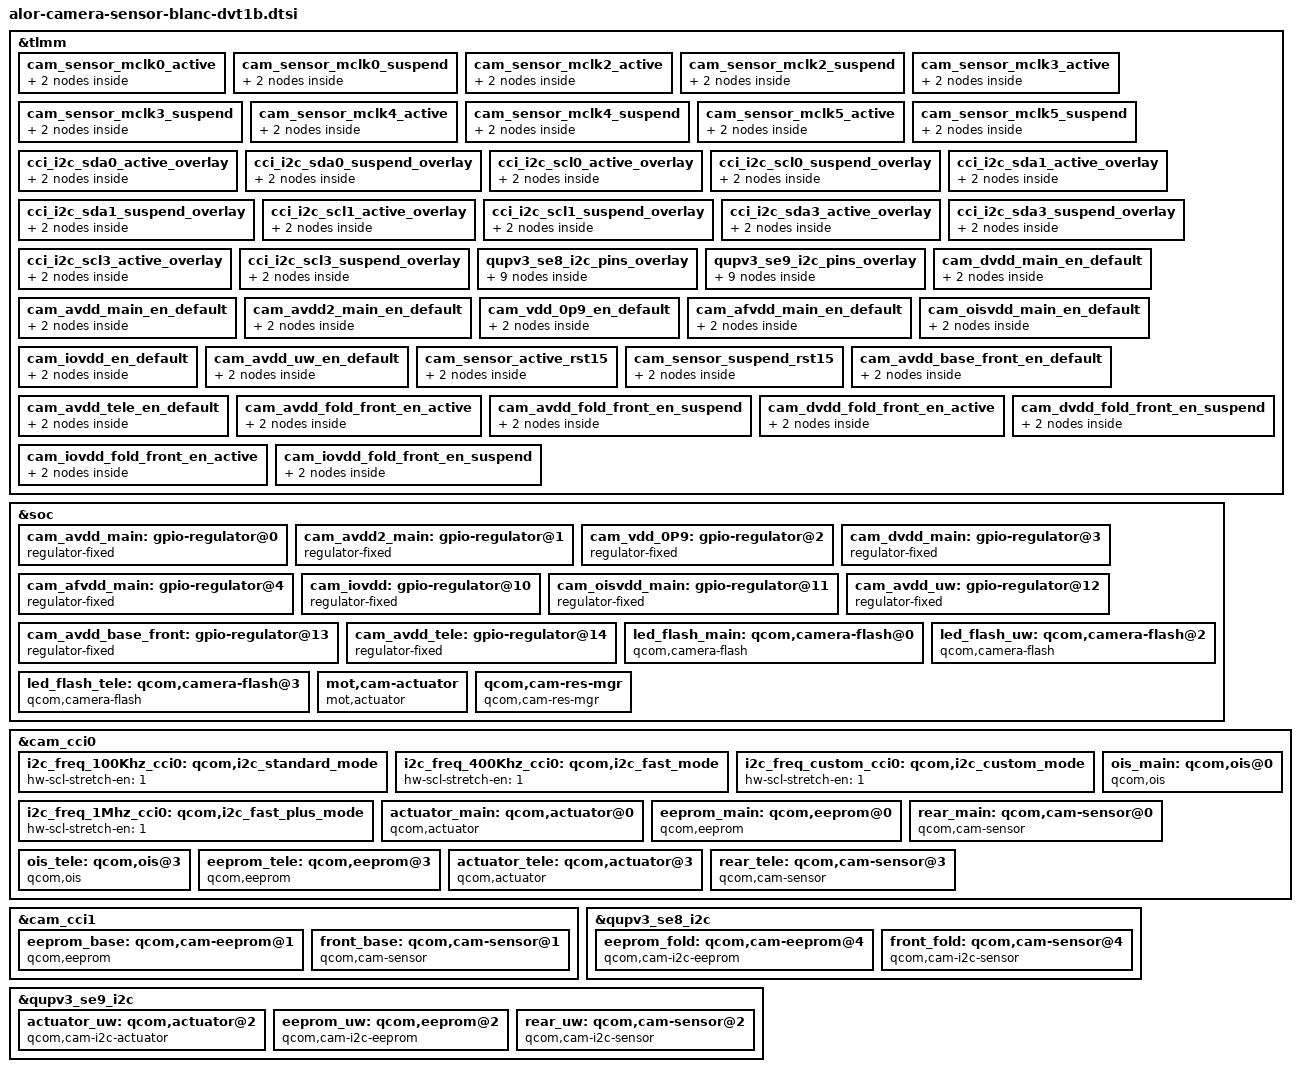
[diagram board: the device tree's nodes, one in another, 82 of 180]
// SPDX-License-Identifier: BSD-3-Clause
/*
 * Copyright (c) 2024 Qualcomm Innovation Center, Inc. All rights reserved.
 */

#include <dt-bindings/msm-camera.h>

&tlmm {
	cam_sensor_mclk0_active: cam_sensor_mclk0_active {
		/* MCLK0 */
		mux {
			pins = "gpio89";
			function = "cam_mclk";
		};

		config {
			pins = "gpio89";
			bias-disable; /* No PULL */
			drive-strength = <4>; /* 4 MA */
		};
	};

	cam_sensor_mclk0_suspend: cam_sensor_mclk0_suspend {
		/* MCLK0 */
		mux {
			pins = "gpio89";
			function = "cam_mclk";
		};

		config {
			pins = "gpio89";
			bias-pull-down; /* PULL DOWN */
			drive-strength = <4>; /* 4 MA */
		};
	};

	cam_sensor_mclk2_active: cam_sensor_mclk2_active {
		/* MCLK2 */
		mux {
			pins = "gpio91";
			function = "cam_mclk";
		};

		config {
			pins = "gpio91";
			bias-disable; /* No PULL */
			drive-strength = <4>; /* 4 MA */
		};
	};

	cam_sensor_mclk2_suspend: cam_sensor_mclk2_suspend {
		/* MCLK2 */
		mux {
			pins = "gpio91";
			function = "cam_mclk";
		};

		config {
			pins = "gpio91";
			bias-pull-down; /* PULL DOWN */
			drive-strength = <4>; /* 4 MA */
		};
	};

	cam_sensor_mclk3_active: cam_sensor_mclk3_active {
		/* MCLK3 */
		mux {
			pins = "gpio92";
			function = "cam_mclk";
		};

		config {
			pins = "gpio92";
			bias-disable; /* No PULL */
			drive-strength = <4>; /* 4 MA */
		};
	};

	cam_sensor_mclk3_suspend: cam_sensor_mclk3_suspend {
		/* MCLK3 */
		mux {
			pins = "gpio92";
			function = "cam_mclk";
		};

		config {
			pins = "gpio92";
			bias-pull-down; /* PULL DOWN */
			drive-strength = <4>; /* 4 MA */
		};
	};

	cam_sensor_mclk4_active: cam_sensor_mclk4_active {
		/* MCLK4 */
		mux {
			pins = "gpio93";
			function = "cam_asc_mclk4";
		};

		config {
			pins = "gpio93";
			bias-disable; /* No PULL */
			drive-strength = <6>; /* 6 MA */
		};
	};

	cam_sensor_mclk4_suspend: cam_sensor_mclk4_suspend {
		/* MCLK4 */
		mux {
			pins = "gpio93";
			function = "cam_asc_mclk4";
		};

		config {
			pins = "gpio93";
			bias-pull-down; /* PULL DOWN */
			drive-strength = <6>; /* 6 MA */
		};
	};

	cam_sensor_mclk5_active: cam_sensor_mclk5_active {
		/* MCLK5 */
		mux {
			pins = "gpio94";
			function = "cam_mclk";
		};

		config {
			pins = "gpio94";
			bias-disable; /* No PULL */
			drive-strength = <4>; /* 4 MA */
		};
	};

	cam_sensor_mclk5_suspend: cam_sensor_mclk5_suspend {
		/* MCLK5 */
		mux {
			pins = "gpio94";
			function = "cam_mclk";
		};

		config {
			pins = "gpio94";
			bias-pull-down; /* PULL DOWN */
			drive-strength = <4>; /* 4 MA */
		};
	};

	cci_i2c_sda0_active_overlay: cci_i2c_sda0_active_overlay {
		/* SDA0 */
		mux {
			pins = "gpio113";
			function = "cci_i2c_sda0";
		};

		config {
			pins = "gpio113";
			bias-disable;
			drive-strength = <2>; /* 2 MA */
		};
	};

	cci_i2c_sda0_suspend_overlay: cci_i2c_sda0_suspend_overlay {
		/* SDA0 */
		mux {
			pins = "gpio113";
			function = "cci_i2c_sda0";
		};

		config {
			pins = "gpio113";
			bias-disable;
			drive-strength = <2>; /* 2 MA */
		};
	};

	cci_i2c_scl0_active_overlay: cci_i2c_scl0_active_overlay {
		/* SCL0 */
		mux {
			pins = "gpio114";
			function = "cci_i2c_scl0";
		};

		config {
			pins = "gpio114";
			bias-disable;
			drive-strength = <2>; /* 2 MA */
		};
	};

	cci_i2c_scl0_suspend_overlay: cci_i2c_scl0_suspend_overlay {
		/* SCL0 */
		mux {
			pins = "gpio114";
			function = "cci_i2c_scl0";
		};

		config {
			pins = "gpio114";
			bias-disable;
			drive-strength = <2>; /* 2 MA */
		};
	};

	cci_i2c_sda1_active_overlay: cci_i2c_sda1_active_overlay {
		/* SDA1 */
		mux {
			pins = "gpio115";
			function = "cci_i2c_sda1";
		};

		config {
			pins = "gpio115";
			bias-disable;
			drive-strength = <2>; /* 2 MA */
		};
	};

	cci_i2c_sda1_suspend_overlay: cci_i2c_sda1_suspend_overlay {
		/* SDA1 */
		mux {
			pins = "gpio115";
			function = "cci_i2c_sda1";
		};

		config {
			pins = "gpio115";
			bias-disable;
			drive-strength = <2>; /* 2 MA */
		};
	};

	cci_i2c_scl1_active_overlay: cci_i2c_scl1_active_overlay{
		/* SCL1 */
		mux {
			pins = "gpio116";
			function = "cci_i2c_scl1";
		};

		config {
			pins = "gpio116";
			bias-disable;
			drive-strength = <2>; /* 2 MA */
		};
	};

	cci_i2c_scl1_suspend_overlay: cci_i2c_scl1_suspend_overlay {
		/* SCL1 */
		mux {
			pins = "gpio116";
			function = "cci_i2c_scl1";
		};

		config {
			pins = "gpio116";
			bias-disable;
			drive-strength = <2>; /* 2 MA */
		};
	};

	cci_i2c_sda3_active_overlay: cci_i2c_sda3_active_overlay {
		/* SDA3 */
		mux {
			pins = "gpio111";
			function = "cci_i2c_sda3";
		};

		config {
			pins = "gpio111";
			bias-disable;
			drive-strength = <2>; /* 2 MA */
		};
	};

	cci_i2c_sda3_suspend_overlay: cci_i2c_sda3_suspend_overlay {
		/* SDA3 */
		mux {
			pins = "gpio111";
			function = "cci_i2c_sda3";
		};

		config {
			pins = "gpio111";
			bias-disable;
			drive-strength = <2>; /* 2 MA */
		};
	};

	cci_i2c_scl3_active_overlay: cci_i2c_scl3_active_overlay {
		/* SCL3 */
		mux {
			pins = "gpio7";
			function = "cci_i2c_scl3";
		};

		config {
			pins = "gpio7";
			bias-disable;
			drive-strength = <2>; /* 2 MA */
		};
	};

	cci_i2c_scl3_suspend_overlay: cci_i2c_scl3_suspend_overlay {
		/* SCL3 */
		mux {
			pins = "gpio7";
			function = "cci_i2c_scl3";
		};

		config {
			pins = "gpio7";
			bias-disable;
			drive-strength = <2>; /* 2 MA */
		};
	};

	qupv3_se8_i2c_pins_overlay: qupv3_se8_i2c_pins_overlay {
		qupv3_se8_i2c_sda_active_overlay: qupv3_se8_i2c_sda_active_overlay {
			mux {
				pins = "gpio0";
				function = "qup2_se0_l0";
			};

			config {
				pins = "gpio0";
				drive-strength = <2>;
				bias-disable;
				qcom,apps;
			};
		};

		qupv3_se8_i2c_scl_active_overlay: qupv3_se8_i2c_scl_active_overlay {
			mux {
				pins = "gpio1";
				function = "qup2_se0_l1";
			};

			config {
				pins = "gpio1";
				drive-strength = <2>;
				bias-disable;
				qcom,apps;
			};
		};

		qupv3_se8_i2c_sleep_overlay: qupv3_se8_i2c_sleep_overlay {
			mux {
				pins = "gpio0", "gpio1";
				function = "gpio";
			};

			config {
				pins = "gpio0", "gpio1";
				drive-strength = <2>;
				qcom,remote;
			};
		};
	};

	qupv3_se9_i2c_pins_overlay: qupv3_se9_i2c_pins_overlay {
		qupv3_se9_i2c_sda_active_overlay: qupv3_se9_i2c_sda_active_overlay {
			mux {
				pins = "gpio4";
				function = "qup2_se1_l0";
			};

			config {
				pins = "gpio4";
				drive-strength = <2>;
				bias-disable;
			};
		};

		qupv3_se9_i2c_scl_active_overlay: qupv3_se9_i2c_scl_active_overlay {
			mux {
				pins = "gpio5";
				function = "qup2_se1_l1";
			};

			config {
				pins = "gpio5";
				drive-strength = <2>;
				bias-disable;
			};
		};

		qupv3_se9_i2c_sleep_overlay: qupv3_se9_i2c_sleep_overlay {
			mux {
				pins = "gpio4", "gpio5";
				function = "gpio";
			};

			config {
				pins = "gpio4", "gpio5";
				drive-strength = <2>;
			};
		};
	};

	cam_dvdd_main_en_default: cam_dvdd_main_en_default {
		mux {
			pins = "gpio56";
			function = "gpio";
		};

		config {
			pins = "gpio56";
			bias-pull-down; /* PULL DOWN */
			drive-strength = <2>; /* 2 MA */
		};
	};

	cam_avdd_main_en_default: cam_avdd_main_en_default {
		mux {
			pins = "gpio129";
			function = "gpio";
		};

		config {
			pins = "gpio129";
			bias-pull-down; /* PULL DOWN */
			drive-strength = <2>; /* 2 MA */
		};
	};

	cam_avdd2_main_en_default: cam_avdd2_main_en_default {
		mux {
			pins = "gpio128";
			function = "gpio";
		};

		config {
			pins = "gpio128";
			bias-pull-down; /* PULL DOWN */
			drive-strength = <2>; /* 2 MA */
		};
	};

	cam_vdd_0p9_en_default: cam_vdd_0p9_en_default {
		mux {
			pins = "gpio100";
			function = "gpio";
		};

		config {
			pins = "gpio100";
			bias-pull-down; /* PULL DOWN */
			drive-strength = <2>; /* 2 MA */
		};
	};

	cam_afvdd_main_en_default: cam_afvdd_main_en_default {
		mux {
			pins = "gpio14";
			function = "gpio";
		};

		config {
			pins = "gpio14";
			bias-pull-down; /* PULL DOWN */
			drive-strength = <2>; /* 2 MA */
		};
	};

	cam_oisvdd_main_en_default: cam_oisvdd_main_en_default {
		mux {
			pins = "gpio75";
			function = "gpio";
		};

		config {
			pins = "gpio75";
			bias-pull-down; /* PULL DOWN */
			drive-strength = <2>; /* 2 MA */
		};
	};

	cam_iovdd_en_default: cam_iovdd_en_default {
		mux {
			pins = "gpio192";
			function = "gpio";
		};

		config {
			pins = "gpio192";
			bias-pull-down; /* PULL DOWN */
			drive-strength = <2>; /* 2 MA */
		};
	};

	cam_avdd_uw_en_default: cam_avdd_uw_en_default {
		mux {
			pins = "gpio127";
			function = "gpio";
		};

		config {
			pins = "gpio127";
			bias-pull-down; /* PULL DOWN */
			drive-strength = <2>; /* 2 MA */
		};
	};

	cam_sensor_active_rst15: cam_sensor_active_rst15 {
		mux {
			pins = "gpio15";
			function = "gpio";
		};

		config {
			pins = "gpio15";
			bias-disable; /* No PULL */
			drive-strength = <2>; /* 2 MA */
		};
	};

	cam_sensor_suspend_rst15: cam_sensor_suspend_rst15 {
		mux {
			pins = "gpio15";
			function = "gpio";
		};

		config {
			pins = "gpio15";
			bias-pull-down; /* PULL DOWN */
			drive-strength = <2>; /* 2 MA */
			output-low;
		};
	};

	cam_avdd_base_front_en_default: cam_avdd_base_front_en_default {
		mux {
			pins = "gpio57";
			function = "gpio";
		};

		config {
			pins = "gpio57";
			bias-pull-down; /* PULL DOWN */
			drive-strength = <2>; /* 2 MA */
		};
	};

	cam_avdd_tele_en_default: cam_avdd_tele_en_default {
		mux {
			pins = "gpio126";
			function = "gpio";
		};

		config {
			pins = "gpio126";
			bias-pull-down; /* PULL DOWN */
			drive-strength = <2>; /* 2 MA */
		};
	};

	cam_avdd_fold_front_en_active: cam_avdd_fold_front_en_active {
		mux {
			pins = "gpio22";
			function = "gpio";
		};
		config {
			pins = "gpio22";
			bias-disable;
			drive-strength = <2>; /* 2 MA */
			qcom,apps;
		};
	};

	cam_avdd_fold_front_en_suspend: cam_avdd_fold_front_en_suspend {
		mux {
			pins = "gpio22";
			function = "gpio";
		};
		config {
			pins = "gpio22";
			bias-pull-down; /* PULL DOWN */
			drive-strength = <2>; /* 2 MA */
			output-low;
			qcom,remote;
		};
	};

	cam_dvdd_fold_front_en_active: cam_dvdd_fold_front_en_active {
		mux {
			pins = "gpio153";
			function = "gpio";
		};
		config {
			pins = "gpio153";
			bias-disable;
			drive-strength = <2>; /* 2 MA */
			qcom,apps;
		};
	};

	cam_dvdd_fold_front_en_suspend: cam_dvdd_fold_front_en_suspend {
		mux {
			pins = "gpio153";
			function = "gpio";
		};
		config {
			pins = "gpio153";
			bias-pull-down; /* PULL DOWN */
			drive-strength = <2>; /* 2 MA */
			output-low;
			qcom,remote;
		};
	};

	cam_iovdd_fold_front_en_active: cam_iovdd_fold_front_en_active {
		mux {
			pins = "gpio202";
			function = "gpio";
		};
		config {
			pins = "gpio202";
			bias-disable;
			drive-strength = <2>; /* 2 MA */
			qcom,apps;
		};
	};

	cam_iovdd_fold_front_en_suspend: cam_iovdd_fold_front_en_suspend {
		mux {
			pins = "gpio202";
			function = "gpio";
		};
		config {
			pins = "gpio202";
			bias-pull-down; /* PULL DOWN */
			drive-strength = <2>; /* 2 MA */
			output-low;
			qcom,remote;
		};
	};
};

&soc {
	cam_avdd_main: gpio-regulator@0 {
		compatible = "regulator-fixed";
		reg = <0x00 0x00>;
		regulator-name = "cam_avdd_main";
		regulator-min-microvolt = <1800000>;
		regulator-max-microvolt = <1800000>;
		regulator-enable-ramp-delay = <233>;
		enable-active-high;
		gpio = <&tlmm 129 0>;
		pinctrl-names = "default";
		pinctrl-0 = <&cam_avdd_main_en_default>;
		vin-supply = <&S4D>;
	};

	cam_avdd2_main: gpio-regulator@1 {
		compatible = "regulator-fixed";
		reg = <0x01 0x00>;
		regulator-name = "cam_avdd2_main";
		regulator-min-microvolt = <2800000>;
		regulator-max-microvolt = <2800000>;
		regulator-enable-ramp-delay = <233>;
		enable-active-high;
		gpio = <&tlmm 128 0>;
		pinctrl-names = "default";
		pinctrl-0 = <&cam_avdd2_main_en_default>;
		vin-supply = <&vdd_cam_3p0>;
	};

	cam_vdd_0P9: gpio-regulator@2 {
		compatible = "regulator-fixed";
		reg = <0x02 0x00>;
		regulator-name = "cam_vdd_0P9";
		regulator-min-microvolt = <900000>;
		regulator-max-microvolt = <900000>;
		regulator-enable-ramp-delay = <233>;
		enable-active-high;
		gpio = <&tlmm 100 0>;
		pinctrl-names = "default";
		pinctrl-0 = <&cam_vdd_0p9_en_default>;
		//vin-supply = <&BOB1>; //B_PLUS
	};

	cam_dvdd_main: gpio-regulator@3 {
		compatible = "regulator-fixed";
		reg = <0x03 0x00>;
		regulator-name = "cam_dvdd_main";
		regulator-min-microvolt = <810000>;
		regulator-max-microvolt = <810000>;
		regulator-enable-ramp-delay = <233>;
		enable-active-high;
		gpio = <&tlmm 56 0>;
		pinctrl-names = "default";
		pinctrl-0 = <&cam_dvdd_main_en_default>;
		vin-supply = <&cam_vdd_0P9>;
	};

	cam_afvdd_main: gpio-regulator@4 {
		compatible = "regulator-fixed";
		reg = <0x04 0x00>;
		regulator-name = "cam_afvdd_main";
		regulator-min-microvolt = <3000000>;
		regulator-max-microvolt = <3000000>;
		regulator-enable-ramp-delay = <233>;
		enable-active-high;
		gpio = <&tlmm 14 0>;
		pinctrl-names = "default";
		pinctrl-0 = <&cam_afvdd_main_en_default>;
		vin-supply = <&BOB1>;
	};

	cam_iovdd: gpio-regulator@10 {
		compatible = "regulator-fixed";
		reg = <0x10 0x00>;
		regulator-name = "cam_iovdd";
		regulator-min-microvolt = <1800000>;
		regulator-max-microvolt = <1800000>;
		regulator-enable-ramp-delay = <233>;
		enable-active-high;
		gpio = <&tlmm 192 0>;
		pinctrl-names = "default";
		pinctrl-0 = <&cam_iovdd_en_default>;
		vin-supply = <&S4D>;
	};

	cam_oisvdd_main: gpio-regulator@11 {
		compatible = "regulator-fixed";
		reg = <0x11 0x00>;
		regulator-name = "cam_oisvdd_main";
		regulator-min-microvolt = <3200000>;
		regulator-max-microvolt = <3200000>;
		regulator-enable-ramp-delay = <233>;
		enable-active-high;
		gpio = <&tlmm 75 0>;
		pinctrl-names = "default";
		pinctrl-0 = <&cam_oisvdd_main_en_default>;
		vin-supply = <&BOB1>;
	};

	cam_avdd_uw: gpio-regulator@12 {
		compatible = "regulator-fixed";
		reg = <0x12 0x00>;
		regulator-name = "cam_avdd_uw";
		regulator-min-microvolt = <2800000>;
		regulator-max-microvolt = <2800000>;
		regulator-enable-ramp-delay = <233>;
		enable-active-high;
		gpio = <&tlmm 127 0>;
		pinctrl-names = "default";
		pinctrl-0 = <&cam_avdd_uw_en_default>;
		vin-supply = <&vdd_cam_3p0>;
	};

	cam_avdd_base_front: gpio-regulator@13 {
		compatible = "regulator-fixed";
		reg = <0x13 0x00>;
		regulator-name = "cam_avdd_base_front";
		regulator-min-microvolt = <2800000>;
		regulator-max-microvolt = <2800000>;
		regulator-enable-ramp-delay = <233>;
		enable-active-high;
		gpio = <&tlmm 57 0>;
		pinctrl-names = "default";
		pinctrl-0 = <&cam_avdd_base_front_en_default>;
		vin-supply = <&vdd_cam_3p0>;
	};

	cam_avdd_tele: gpio-regulator@14 {
		compatible = "regulator-fixed";
		reg = <0x14 0x00>;
		regulator-name = "cam_avdd_tele";
		regulator-min-microvolt = <2800000>;
		regulator-max-microvolt = <2800000>;
		regulator-enable-ramp-delay = <233>;
		enable-active-high;
		gpio = <&tlmm 126 0>;
		pinctrl-names = "default";
		pinctrl-0 = <&cam_avdd_tele_en_default>;
		vin-supply = <&vdd_cam_3p0>;
	};

	led_flash_main: qcom,camera-flash@0 {
		cell-index = <0>;
		compatible = "qcom,camera-flash";
		leds = <&pm8550_flash_led0>;
		status = "ok";
	};

	led_flash_uw: qcom,camera-flash@2 {
		cell-index = <2>;
		compatible = "qcom,camera-flash";
		leds = <&pm8550_flash_led0>;
		status = "ok";
	};

	led_flash_tele: qcom,camera-flash@3 {
		cell-index = <3>;
		compatible = "qcom,camera-flash";
		leds = <&pm8550_flash_led0>;
		status = "ok";
	};

	/* main camera lens protection */
	mot,cam-actuator {
		compatible = "mot,actuator";
		status = "ok";
	};

	qcom,cam-res-mgr {
		compatible = "qcom,cam-res-mgr";
		status = "ok";
	};
};

&cam_cci0 {
	pinctrl-0 = <&cci_i2c_scl0_active_overlay &cci_i2c_sda0_active_overlay>;
	pinctrl-1 = <&cci_i2c_scl0_suspend_overlay &cci_i2c_sda0_suspend_overlay>;
	pinctrl-2 = <&cci_i2c_scl1_active_overlay &cci_i2c_sda1_active_overlay>;
	pinctrl-3 = <&cci_i2c_scl1_suspend_overlay &cci_i2c_sda1_suspend_overlay>;

	i2c_freq_100Khz_cci0: qcom,i2c_standard_mode {
		hw-scl-stretch-en = <1>;
	};

	i2c_freq_400Khz_cci0: qcom,i2c_fast_mode {
		hw-scl-stretch-en = <1>;
	};

	i2c_freq_custom_cci0: qcom,i2c_custom_mode {
		hw-scl-stretch-en = <1>;
	};

	i2c_freq_1Mhz_cci0: qcom,i2c_fast_plus_mode {
		hw-scl-stretch-en = <1>;
	};

	actuator_main: qcom,actuator@0 {
		cell-index = <0>;
		compatible = "qcom,actuator";
		cci-master = <CCI_MASTER_0>;
		cam_vaf-supply = <&cam_afvdd_main>;
		regulator-names = "cam_vaf";
		rgltr-cntrl-support;
		rgltr-min-voltage = <3000000>;
		rgltr-max-voltage = <3000000>;
		rgltr-load-current = <119000>;
		af-drift-support;
		status = "ok";
		multi-user-support;
	};

	eeprom_main: qcom,eeprom@0 {
		cell-index = <0>;
		compatible = "qcom,eeprom";
		cam_vio-supply = <&cam_iovdd>;
		cam_vdig-supply = <&cam_dvdd_main>;
		power-domains = <&camcc CAM_CC_TITAN_TOP_GDSC>;
		cam_vana-supply = <&cam_avdd2_main>;
		cam_v_custom1-supply = <&cam_avdd_main>;
		regulator-names = "cam_vio", "cam_vdig","cam_vana", "cam_v_custom1";
		rgltr-cntrl-support;
		rgltr-min-voltage = <1800000 810000 2800000 1800000>;
		rgltr-max-voltage = <1800000 810000 2800000 1800000>;
		rgltr-load-current = <3500 913200 91430 63100>;
		gpio-no-mux = <0>;
		pinctrl-names = "cam_default", "cam_suspend";
		pinctrl-0 = <&cam_sensor_mclk2_active &cam_sensor_active_rst2>;
		pinctrl-1 = <&cam_sensor_mclk2_suspend &cam_sensor_suspend_rst2>;
		gpios = <&tlmm 91 0>,<&tlmm 90 0>;
		gpio-reset = <1>;
		gpio-req-tbl-num = <0 1>;
		gpio-req-tbl-flags = <1 0>;
		gpio-req-tbl-label = "CAMIF_MCLK2","CAM_RESET2";
		cci-master = <CCI_MASTER_0>;
		clocks = <&cambistmclkcc CAM_BIST_MCLK_CC_MCLK2_CLK>;
		clock-names = "cam_clk";
		clock-cntl-level = "nominal";
		clock-rates = <19200000>;
		status = "ok";
	};

	ois_main: qcom,ois@0 {
		cell-index = <0>;
		compatible = "qcom,ois";
		cci-master = <CCI_MASTER_0>;
		cam_vio-supply = <&cam_iovdd>;
		cam_vaf-supply = <&cam2_ldo4>;
		cam_v_custom1-supply = <&cam_oisvdd_main>;
		power-domains = <&camcc CAM_CC_TITAN_TOP_GDSC>;
		regulator-names = "cam_vio", "cam_vaf", "cam_v_custom1";
		rgltr-cntrl-support;
		rgltr-min-voltage = <1800000 2900000 3200000>;
		rgltr-max-voltage = <1800000 2900000 3200000>;
		rgltr-load-current = <3500 140000 214290>;
		af-drift-support;
		status = "ok";
	};

	rear_main: qcom,cam-sensor@0 {
		cell-index = <0>;
		compatible = "qcom,cam-sensor";
		csiphy-sd-index = <2>;

		sensor-position-roll  = <90>;
		sensor-position-pitch = <0>;
		sensor-position-yaw   = <180>;

		eeprom-src    = <&eeprom_main>;
		ois-src       = <&ois_main>;
		actuator-src  = <&actuator_main>;
		led-flash-src = <&led_flash_main>;

		cam_vio-supply       = <&cam_iovdd>;
		cam_vdig-supply      = <&cam_dvdd_main>;
		power-domains        = <&camcc CAM_CC_TITAN_TOP_GDSC>;
		cam_vana-supply      = <&cam_avdd2_main>;
		cam_v_custom1-supply = <&cam_avdd_main>;
		regulator-names    = "cam_vio","cam_vdig","cam_vana","cam_v_custom1";
		rgltr-cntrl-support;
		rgltr-min-voltage  = <1800000 810000 2800000 1800000>;
		rgltr-max-voltage  = <1800000 810000 2800000 1800000>;
		rgltr-load-current = <3500    913200   91430   63100>;

		gpio-no-mux = <0>;
		pinctrl-names = "cam_default","cam_suspend";
		pinctrl-0     = <&cam_sensor_mclk2_active  &cam_sensor_active_rst2>;
		pinctrl-1     = <&cam_sensor_mclk2_suspend &cam_sensor_suspend_rst2>;
		gpios              = <&tlmm 91 0>,<&tlmm 90 0>;
		gpio-reset         = <1>;
		gpio-req-tbl-num   = <0 1>;
		gpio-req-tbl-flags = <1 0>;
		gpio-req-tbl-label = "CAMIF_MCLK2","CAM_RESET2";

		cci-master = <CCI_MASTER_0>;

		clocks           = <&cambistmclkcc CAM_BIST_MCLK_CC_MCLK2_CLK>;
		clock-names      = "cam_clk";
		clock-cntl-level = "nominal";
		clock-rates      = <19200000>;

		status = "ok";
	};

	ois_tele: qcom,ois@3 {
		cell-index = <3>;
		compatible = "qcom,ois";
		cci-master = <CCI_MASTER_1>;
		cam_vio-supply = <&cam_iovdd>;
		cam_v_custom2-supply  = <&cam_ldo3>;
		power-domains = <&camcc CAM_CC_TITAN_TOP_GDSC>;
		regulator-names = "cam_vio", "cam_v_custom2";
		rgltr-cntrl-support;
		rgltr-min-voltage = <1800000 2800000>;
		rgltr-max-voltage = <1800000 2800000>;
		rgltr-load-current = <3500 20000>;
		status = "ok";
	};

	eeprom_tele: qcom,eeprom@3 {
		cell-index = <3>;
		reg = <0x3>;
		compatible = "qcom,eeprom";
		cam_vio-supply = <&cam_iovdd>;
		cam_vaf-supply = <&cam_ldo4>;
		cam_v_custom2-supply = <&cam_ldo3>;
		regulator-names = "cam_vio","cam_vaf","cam_v_custom2";
		rgltr-cntrl-support;
		rgltr-min-voltage = <1800000 2800000 2800000>;
		rgltr-max-voltage = <1800000 2800000 2800000>;
		rgltr-load-current = <120000 103000 103000>;
		cci-master = <CCI_MASTER_1>;
		status = "ok";
	};

	actuator_tele: qcom,actuator@3 {
		cell-index = <3>;
		compatible = "qcom,actuator";
		cci-master = <CCI_MASTER_1>;
		cam_vaf-supply = <&cam_ldo4>;
		regulator-names = "cam_vaf";
		rgltr-cntrl-support;
		rgltr-min-voltage = <2800000>;
		rgltr-max-voltage = <2800000>;
		rgltr-load-current = <103000>;
		status = "ok";
	};

	rear_tele: qcom,cam-sensor@3 {
		cell-index = <3>;
		compatible = "qcom,cam-sensor";
		csiphy-sd-index = <1>;

		sensor-position-roll  = <90>;
		sensor-position-pitch = <0>;
		sensor-position-yaw   = <180>;

		eeprom-src    = <&eeprom_tele>;
		ois-src       = <&ois_tele>;
		actuator-src  = <&actuator_tele>;
		led-flash-src = <&led_flash_tele>;

		cam_vio-supply  = <&cam_iovdd>;
		cam_vdig-supply = <&cam_ldo2>;
		power-domains   = <&camcc CAM_CC_TITAN_TOP_GDSC>;
		cam_vana-supply = <&cam_avdd_tele>;
		cam_vaf-supply  = <&cam_ldo4>;
		regulator-names = "cam_vio","cam_vdig","cam_vana","cam_vaf";
		rgltr-cntrl-support;
		rgltr-min-voltage = <1800000 1104000 2800000 2800000>;
		rgltr-max-voltage = <1800000 1104000 2800000 2800000>;
		rgltr-load-current = <3500    913200   91430  103000>;

		gpio-no-mux = <0>;
		pinctrl-names = "cam_default", "cam_suspend";
		pinctrl-0 = <&cam_sensor_mclk0_active &cam_sensor_active_rst1>;
		pinctrl-1 = <&cam_sensor_mclk0_suspend &cam_sensor_suspend_rst1>;

		gpios = <&tlmm 89 0>,
			<&tlmm 163 0>;
		gpio-reset = <1>;
		gpio-req-tbl-num = <0 1>;
		gpio-req-tbl-flags = <1 0>;
		gpio-req-tbl-label = "CAMIF_MCLK0",
					"CAM_RESET1";
		cci-master = <CCI_MASTER_1>;
		clocks = <&cambistmclkcc CAM_BIST_MCLK_CC_MCLK0_CLK>;
		clock-names = "cam_clk";
		clock-cntl-level = "nominal";
		clock-rates = <19200000>;

		status = "ok";
	};
};

&cam_cci1 {
	pinctrl-2 = <&cci_i2c_scl3_active_overlay &cci_i2c_sda3_active_overlay>;
	pinctrl-3 = <&cci_i2c_scl3_suspend_overlay &cci_i2c_sda3_suspend_overlay>;

	eeprom_base: qcom,cam-eeprom@1 {
		cell-index = <1>;
		compatible = "qcom,eeprom";
		cam_vio-supply = <&cam_iovdd>;
		regulator-names ="cam_vio";
		rgltr-cntrl-support;
		rgltr-min-voltage = <1800000>;
		rgltr-max-voltage = <1800000>;
		rgltr-load-current = <3500>;
		cci-master = <CCI_MASTER_1>;
		status = "ok";
	};

	front_base: qcom,cam-sensor@1 {
		cell-index = <1>;
		compatible = "qcom,cam-sensor";
		csiphy-sd-index = <0>;
		sensor-position-roll  = <270>;
		sensor-position-pitch = <0>;
		sensor-position-yaw   = <0>;

		eeprom-src   = <&eeprom_base>;
		cam_vio-supply  = <&cam_iovdd>;
		cam_vdig-supply = <&cam2_ldo2>;
		power-domains   = <&camcc CAM_CC_TITAN_TOP_GDSC>;
		cam_vana-supply = <&cam_avdd_base_front>;
		regulator-names = "cam_vio","cam_vdig","cam_vana";
		rgltr-cntrl-support;
		rgltr-min-voltage = <1800000 1050000 2800000>;
		rgltr-max-voltage = <1800000 1050000 2800000>;
		rgltr-load-current = <3500    913200   91430>;

		gpio-no-mux = <0>;
		pinctrl-names = "cam_default", "cam_suspend";
		pinctrl-0 = <&cam_sensor_mclk5_active  &cam_sensor_active_rst15>;
		pinctrl-1 = <&cam_sensor_mclk5_suspend &cam_sensor_suspend_rst15>;
		gpios              = <&tlmm 94 0>,
                                     <&tlmm 15 0>;
		gpio-reset         = <1>;
		gpio-req-tbl-num   = <0 1>;
		gpio-req-tbl-flags = <1 0>;
		gpio-req-tbl-label = "CAMIF_MCLK5",
                                     "CAM_RESET15";
		cci-master = <CCI_MASTER_1>;
		clocks           = <&cambistmclkcc CAM_BIST_MCLK_CC_MCLK5_CLK>;
		clock-names      = "cam_clk";
		clock-cntl-level = "nominal";
		clock-rates      = <19200000>;
		status = "ok";
	};
};

&qupv3_se8_i2c {
	pinctrl-0 = <&qupv3_se8_i2c_sda_active_overlay>, <&qupv3_se8_i2c_scl_active_overlay>;
	pinctrl-1 = <&qupv3_se8_i2c_sleep_overlay>;

	status = "ok";
	qcom,high-perf;
	qcom,clk-freq-out = <1000000>;
	qcom,pm-ctrl-client;

	eeprom_fold: qcom,cam-eeprom@4 {
		cell-index = <4>;
		reg = <0x50>;
		compatible = "qcom,cam-i2c-eeprom";
		aon-custom-power-support;
		gpio-no-mux = <0>;
		pinctrl-names = "cam_default", "cam_suspend";
		pinctrl-0 = <&cam_iovdd_fold_front_en_active>;
		pinctrl-1 = <&cam_iovdd_fold_front_en_suspend>;
		gpios = <&tlmm 202 0>;
		gpio-vio = <0>;
		gpio-req-tbl-num = <0>;
		gpio-req-tbl-flags = <0>;
		gpio-req-tbl-label = "CAM_VIO4";
		status = "ok";
	};

	front_fold: qcom,cam-sensor@4 {
		cell-index = <4>;
		reg = <0x36>;
		compatible = "qcom,cam-i2c-sensor";
		csiphy-sd-index = <4>;
		sensor-position-roll = <270>;
		sensor-position-pitch = <0>;
		sensor-position-yaw = <0>;
		eeprom-src   = <&eeprom_fold>;
		power-domains   = <&camcc CAM_CC_TITAN_TOP_GDSC>;
		aon-camera-id = <AON_CAM1>;
		aon-custom-power-support;
		gpio-no-mux = <0>;
		pinctrl-names = "cam_default", "cam_suspend";
		pinctrl-0 = <&cam_sensor_mclk4_active &cam_sensor_active_rst4 &cam_avdd_fold_front_en_active &cam_dvdd_fold_front_en_active &cam_iovdd_fold_front_en_active>;
		pinctrl-1 = <&cam_sensor_mclk4_suspend &cam_sensor_suspend_rst4 &cam_avdd_fold_front_en_suspend &cam_dvdd_fold_front_en_suspend &cam_iovdd_fold_front_en_suspend>;
		gpios = <&tlmm 93 0>,
			<&tlmm 3 0>,
			<&tlmm 22 0>,
			<&tlmm 153 0>,
			<&tlmm 202 0>;
		gpio-reset = <1>;
		gpio-vana = <2>;
		gpio-vdig = <3>;
		gpio-vio = <4>;
		gpio-req-tbl-num = <0 1 2 3 4>;
		gpio-req-tbl-flags = <1 0 0 0 0>;
		gpio-req-tbl-label = "CAMIF_MCLK4","CAM_RESET4","CAM_VANA4","CAM_VDIG4","CAM_VIO4";
		clocks = <&cambistmclkcc CAM_BIST_MCLK_CC_MCLK4_CLK>;
		clock-names = "cam_clk";
		clock-cntl-level = "nominal";
		clock-rates = <19200000>;
		status = "ok";
	};
};

&qupv3_se9_i2c {
	pinctrl-0 = <&qupv3_se9_i2c_sda_active_overlay>, <&qupv3_se9_i2c_scl_active_overlay>;
	pinctrl-1 = <&qupv3_se9_i2c_sleep_overlay>;

	status = "ok";
	qcom,high-perf;
	qcom,clk-freq-out = <1000000>;
	qcom,pm-ctrl-client;

	actuator_uw: qcom,actuator@2 {
		cell-index = <2>;
		reg = <0x0c>;
		compatible = "qcom,cam-i2c-actuator";
		cam_vaf-supply = <&cam2_ldo3>;
		regulator-names = "cam_vaf";
		rgltr-cntrl-support;
		rgltr-min-voltage = <2800000>;
		rgltr-max-voltage = <2800000>;
		rgltr-load-current = <103000>;
		status = "ok";
	};

	eeprom_uw: qcom,eeprom@2 {
		cell-index = <2>;
		reg = <0x50>;
		compatible = "qcom,cam-i2c-eeprom";

		cam_vio-supply  = <&cam_iovdd>;
		cam_vdig-supply = <&cam2_ldo1>;
		power-domains   = <&camcc CAM_CC_TITAN_TOP_GDSC>;
		cam_vana-supply = <&cam_avdd_uw>;

		regulator-names = "cam_vio","cam_vdig","cam_vana";
		rgltr-cntrl-support;

		rgltr-min-voltage = <1800000 1050000 2800000>;
		rgltr-max-voltage = <1800000 1050000 2800000>;
		rgltr-load-current = <3000    283000   50000 >;

		gpio-no-mux = <0>;
		pinctrl-names = "cam_default", "cam_suspend";
		pinctrl-0 = <&cam_sensor_mclk3_active  &cam_sensor_active_rst3>;
		pinctrl-1 = <&cam_sensor_mclk3_suspend &cam_sensor_suspend_rst3>;

		gpios = <&tlmm 92 0>,
			<&tlmm 6 0>;
		gpio-reset = <1>;
		gpio-req-tbl-num = <0 1>;
		gpio-req-tbl-flags = <1 0>;
		gpio-req-tbl-label = "CAMIF_MCLK3","CAM_RESET3";

		clocks = <&cambistmclkcc CAM_BIST_MCLK_CC_MCLK3_CLK>;
		clock-names      = "cam_clk";
		clock-cntl-level = "nominal";
		clock-rates      = <19200000>;
		status = "ok";

	};

	rear_uw: qcom,cam-sensor@2 {
		cell-index = <2>;
		reg = <0x10>;
		compatible = "qcom,cam-i2c-sensor";
		csiphy-sd-index = <3>;

		sensor-position-roll  = <90>;
		sensor-position-pitch = <0>;
		sensor-position-yaw   = <180>;

		eeprom-src    = <&eeprom_uw>;
		actuator-src  = <&actuator_uw>;
		led-flash-src = <&led_flash_uw>;

		cam_vio-supply  = <&cam_iovdd>;
		cam_vdig-supply = <&cam2_ldo1>;
		power-domains   = <&camcc CAM_CC_TITAN_TOP_GDSC>;
		cam_vana-supply = <&cam_avdd_uw>;

		regulator-names = "cam_vio","cam_vdig","cam_vana";
		rgltr-cntrl-support;

		rgltr-min-voltage = <1800000 1050000 2800000>;
		rgltr-max-voltage = <1800000 1050000 2800000>;
		rgltr-load-current = <3000    283000   50000 >;

		gpio-no-mux = <0>;
		pinctrl-names = "cam_default", "cam_suspend";
		pinctrl-0 = <&cam_sensor_mclk3_active  &cam_sensor_active_rst3>;
		pinctrl-1 = <&cam_sensor_mclk3_suspend &cam_sensor_suspend_rst3>;

		gpios = <&tlmm 92 0>,
			<&tlmm 6 0>;
		gpio-reset = <1>;
		gpio-req-tbl-num = <0 1>;
		gpio-req-tbl-flags = <1 0>;
		gpio-req-tbl-label = "CAMIF_MCLK3","CAM_RESET3";

		clocks = <&cambistmclkcc CAM_BIST_MCLK_CC_MCLK3_CLK>;
		clock-names      = "cam_clk";
		clock-cntl-level = "nominal";
		clock-rates      = <19200000>;
		status = "ok";

	};
};
